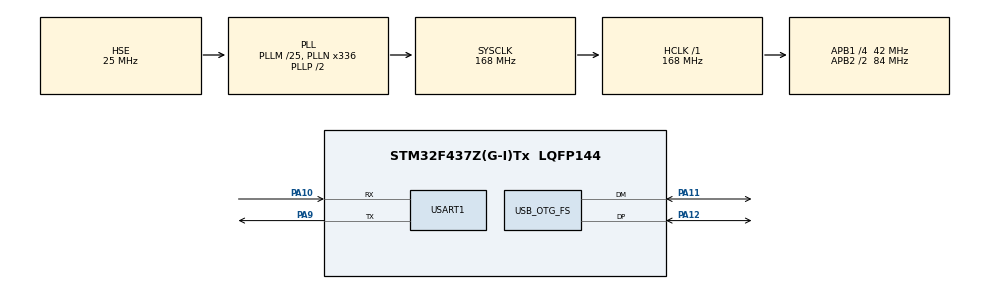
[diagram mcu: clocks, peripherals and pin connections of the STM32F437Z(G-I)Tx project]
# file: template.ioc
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Mcu.Family=STM32F4
Mcu.Name=STM32F437Z(G-I)Tx
Mcu.Package=LQFP144
NVIC.PriorityGroup=NVIC_PRIORITYGROUP_4
PA10.Mode=Asynchronous
PA10.Signal=USART1_RX
PA11.Mode=Host_Only
PA11.Signal=USB_OTG_FS_DM
PA12.Mode=Host_Only
PA12.Signal=USB_OTG_FS_DP
PA9.Mode=Asynchronous
PA9.Signal=USART1_TX
PC14/OSC32_IN.Mode=LSE-External-Oscillator
PC14/OSC32_IN.Signal=RCC_OSC32_IN
PC15/OSC32_OUT.Mode=LSE-External-Oscillator
PC15/OSC32_OUT.Signal=RCC_OSC32_OUT
PH0/OSC_IN.Mode=HSE-External-Oscillator
PH0/OSC_IN.Signal=RCC_OSC_IN
PH1/OSC_OUT.Mode=HSE-External-Oscillator
PH1/OSC_OUT.Signal=RCC_OSC_OUT
ProjectManager.HeapSize=0x200
ProjectManager.StackSize=0x400
ProjectManager.TargetToolchain=MDK-ARM V5
RCC.48MHZClocksFreq_Value=48000000
RCC.AHBFreq_Value=168000000
RCC.APB1CLKDivider=RCC_HCLK_DIV4
RCC.APB1Freq_Value=42000000
RCC.APB1TimFreq_Value=84000000
RCC.APB2CLKDivider=RCC_HCLK_DIV2
RCC.APB2Freq_Value=84000000
RCC.APB2TimFreq_Value=168000000
RCC.CortexFreq_Value=168000000
RCC.HCLKFreq_Value=168000000
RCC.HSE_VALUE=25000000
RCC.HSI_VALUE=16000000
RCC.PLLM=25
RCC.PLLN=336
RCC.PLLQ=7
RCC.SYSCLKFreq_VALUE=168000000
RCC.SYSCLKSource=RCC_SYSCLKSOURCE_PLLCLK
RCC.VCOOutputFreq_Value=336000000
USART1.VirtualMode=VM_ASYNC
USB_OTG_FS.VirtualMode=Host_Only
USB_OTG_FS.phy_itface=HCD_PHY_EMBEDDED
board=custom

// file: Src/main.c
/* USER CODE BEGIN Header */
/**
  ******************************************************************************
  * @file           : main.c
  * @brief          : Main program body
  ******************************************************************************
  * @attention
  *
  * <h2><center>&copy; Copyright (c) 2019 STMicroelectronics.
  * All rights reserved.</center></h2>
  *
  * This software component is licensed by ST under BSD 3-Clause license,
  * the "License"; You may not use this file except in compliance with the
  * License. You may obtain a copy of the License at:
  *                        opensource.org/licenses/BSD-3-Clause
  *
  ******************************************************************************
  */
/* USER CODE END Header */

#include "main.h"

UART_HandleTypeDef huart1;

HCD_HandleTypeDef hhcd_USB_OTG_FS;

void SystemClock_Config(void);
static void MX_GPIO_Init(void);
static void MX_USART1_UART_Init(void);
static void MX_USB_OTG_FS_HCD_Init(void);

void SystemClock_Config(void)
{
  RCC_OscInitTypeDef RCC_OscInitStruct = {0};
  RCC_ClkInitTypeDef RCC_ClkInitStruct = {0};

  /** Configure the main internal regulator output voltage
  */
  __HAL_RCC_PWR_CLK_ENABLE();
  __HAL_PWR_VOLTAGESCALING_CONFIG(PWR_REGULATOR_VOLTAGE_SCALE1);
  /** Initializes the CPU, AHB and APB busses clocks
  */
  RCC_OscInitStruct.OscillatorType = RCC_OSCILLATORTYPE_HSE;
  RCC_OscInitStruct.HSEState = RCC_HSE_ON;
  RCC_OscInitStruct.PLL.PLLState = RCC_PLL_ON;
  RCC_OscInitStruct.PLL.PLLSource = RCC_PLLSOURCE_HSE;
  RCC_OscInitStruct.PLL.PLLM = 25;
  RCC_OscInitStruct.PLL.PLLN = 336;
  RCC_OscInitStruct.PLL.PLLP = RCC_PLLP_DIV2;
  RCC_OscInitStruct.PLL.PLLQ = 7;
  if (HAL_RCC_OscConfig(&RCC_OscInitStruct) != HAL_OK)
  {
    Error_Handler();
  }
  /** Initializes the CPU, AHB and APB busses clocks
  */
  RCC_ClkInitStruct.ClockType = RCC_CLOCKTYPE_HCLK|RCC_CLOCKTYPE_SYSCLK
                              |RCC_CLOCKTYPE_PCLK1|RCC_CLOCKTYPE_PCLK2;
  RCC_ClkInitStruct.SYSCLKSource = RCC_SYSCLKSOURCE_PLLCLK;
  RCC_ClkInitStruct.AHBCLKDivider = RCC_SYSCLK_DIV1;
  RCC_ClkInitStruct.APB1CLKDivider = RCC_HCLK_DIV4;
  RCC_ClkInitStruct.APB2CLKDivider = RCC_HCLK_DIV2;

  if (HAL_RCC_ClockConfig(&RCC_ClkInitStruct, FLASH_LATENCY_5) != HAL_OK)
  {
    Error_Handler();
  }
}

static void MX_USART1_UART_Init(void)
{

  huart1.Instance = USART1;
  huart1.Init.BaudRate = 115200;
  huart1.Init.WordLength = UART_WORDLENGTH_8B;
  huart1.Init.StopBits = UART_STOPBITS_1;
  huart1.Init.Parity = UART_PARITY_NONE;
  huart1.Init.Mode = UART_MODE_TX_RX;
  huart1.Init.HwFlowCtl = UART_HWCONTROL_NONE;
  huart1.Init.OverSampling = UART_OVERSAMPLING_16;
  if (HAL_UART_Init(&huart1) != HAL_OK)
  {
    Error_Handler();
  }

}

static void MX_USB_OTG_FS_HCD_Init(void)
{

  hhcd_USB_OTG_FS.Instance = USB_OTG_FS;
  hhcd_USB_OTG_FS.Init.Host_channels = 8;
  hhcd_USB_OTG_FS.Init.speed = HCD_SPEED_FULL;
  hhcd_USB_OTG_FS.Init.dma_enable = DISABLE;
  hhcd_USB_OTG_FS.Init.phy_itface = HCD_PHY_EMBEDDED;
  hhcd_USB_OTG_FS.Init.Sof_enable = DISABLE;
  if (HAL_HCD_Init(&hhcd_USB_OTG_FS) != HAL_OK)
  {
    Error_Handler();
  }

}

static void MX_GPIO_Init(void)
{

  /* GPIO Ports Clock Enable */
  __HAL_RCC_GPIOC_CLK_ENABLE();
  __HAL_RCC_GPIOH_CLK_ENABLE();
  __HAL_RCC_GPIOA_CLK_ENABLE();

}

/* USER CODE BEGIN 4 */
__attribute__((constructor(1)))
void vsf_core_init(void)
{
	SystemClock_Config();
}

void vsf_uart_init(void)
{
	MX_USART1_UART_Init();
	uint8_t test[] = "this is test data.";

	HAL_UART_Transmit(&huart1, test, sizeof(test), 1000);
}
/* USER CODE END 4 */

void Error_Handler(void)
{
}

/************************ (C) COPYRIGHT STMicroelectronics *****END OF FILE****/
